# STM32H743V register map
File version: 2.4
CPU: CM7 r0p1, little endian, MPU, FPU, 4 interrupt priority bits
Registers are 32-bit, read-write, reset 0x0 unless marked. A register's access mark holds for its fields unless they carry their own. Offsets are from the block's base; [hi:lo] are bit positions; lines under a group give offsets from that group; {n}, {i} and the like mark numbered series.

## CRC — Cryptographic processor
Base 0x58024C00
0x00 DR reset 0xFFFFFFFF — Data register
  [31:0] DR — Data Register
0x00 DR8 8-bit reset 0xFF (alternate view of DR) — Data register - byte sized
  [7:0] DR8 — Data register bits
0x00 DR16 16-bit reset 0xFFFF (alternate view of DR) — Data register - half-word sized
  [15:0] DR16 — Data register bits
0x04 IDR — Independent Data register
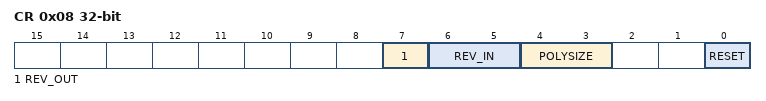
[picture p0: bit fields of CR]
0x08 CR access per field — Control register
  [7] REV_OUT rw — Reverse output data
    0=Normal (Bit order not affected); 1=Reversed (Bit reversed output)
  [6:5] REV_IN rw — Reverse input data
    0=Normal (Bit order not affected); 1=Byte (Bit reversal done by byte); 2=HalfWord (Bit reversal done by half-word); 3=Word (Bit reversal done by word)
  [4:3] POLYSIZE rw — Polynomial size
    0=32-bit polynomial; 1=16-bit polynomial; 2=8-bit polynomial; 3=7-bit polynomial
  [0] RESET wo — RESET bit
    1=Resets the CRC calculation unit and sets the data register to 0xFFFF FFFF
0x10 INIT reset 0xFFFFFFFF — Initial CRC value
  [31:0] INIT — Programmable initial CRC value
0x14 POL reset 0x4C11DB7 — CRC polynomial
  [31:0] POL — Programmable polynomial

## RAMECC1 — ECC controller is associated to each RAM area
Base 0x52009000
Same registers: RAMECC2 0x48023000
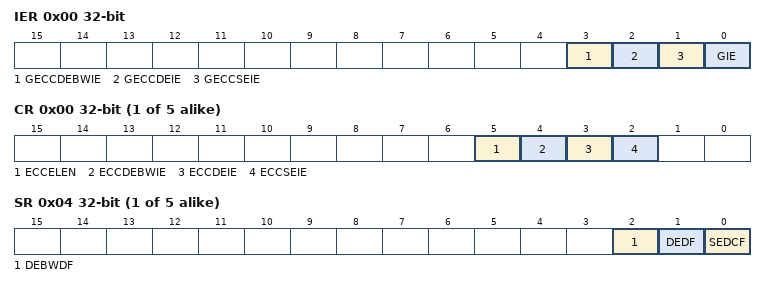
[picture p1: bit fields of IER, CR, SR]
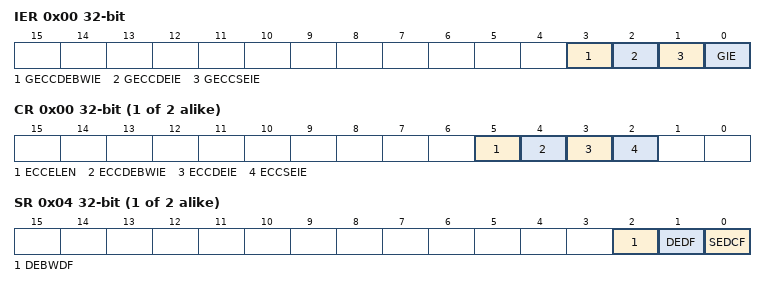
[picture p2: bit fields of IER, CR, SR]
0x00 IER — RAMECC interrupt enable register
  [3] GECCDEBWIE — Global ECC double error on byte write (BW) interrupt enable
  [2] GECCDEIE — Global ECC double error interrupt enable
  [1] GECCSEIE — Global ECC single error interrupt enable
  [0] GIE — Global interrupt enable
{0x0+0x20*i} M{i} (i=1..5) group — Cluster M{i}, containing M?CR, M?SR, M?FAR, M?FDRL, M?FDRH, M?FECR
  0x00 CR — RAMECC monitor x configuration register
    [5] ECCELEN — ECC error latching enable
    [4] ECCDEBWIE — ECC double error on byte write (BW) interrupt enable
    [3] ECCDEIE — ECC double error interrupt enable
    [2] ECCSEIE — ECC single error interrupt enable
  0x04 SR — RAMECC monitor x status register
    [2] DEBWDF — ECC double error on byte write (BW) detected flag
    [1] DEDF — ECC double error detected flag
    [0] SEDCF — ECC single error detected and corrected flag
  0x08 FAR ro — RAMECC monitor x failing address register
    [31:0] FADD — ECC error failing address
  0x0C FDRL ro — RAMECC monitor x failing data low register
    [31:0] FDATAL — Failing data low
  0x10 FDRH ro — RAMECC monitor x failing data high register
    [31:0] FDATAH — Failing data high (64-bit memory)
  0x14 FECR ro — RAMECC monitor x failing ECC error code register
    [31:0] FEC — Failing error code

## RAMECC3 — ECC controller is associated to each RAM area
Base 0x58027000
0x00 IER — RAMECC interrupt enable register
  [3] GECCDEBWIE — Global ECC double error on byte write (BW) interrupt enable
  [2] GECCDEIE — Global ECC double error interrupt enable
  [1] GECCSEIE — Global ECC single error interrupt enable
  [0] GIE — Global interrupt enable
{0x0+0x20*i} M{i} (i=1..2) group — Cluster M{i}, containing M?CR, M?SR, M?FAR, M?FDRL, M?FDRH, M?FECR
  0x00 CR — RAMECC monitor x configuration register
    [5] ECCELEN — ECC error latching enable
    [4] ECCDEBWIE — ECC double error on byte write (BW) interrupt enable
    [3] ECCDEIE — ECC double error interrupt enable
    [2] ECCSEIE — ECC single error interrupt enable
  0x04 SR — RAMECC monitor x status register
    [2] DEBWDF — ECC double error on byte write (BW) detected flag
    [1] DEDF — ECC double error detected flag
    [0] SEDCF — ECC single error detected and corrected flag
  0x08 FAR ro — RAMECC monitor x failing address register
    [31:0] FADD — ECC error failing address
  0x0C FDRL ro — RAMECC monitor x failing data low register
    [31:0] FDATAL — Failing data low
  0x10 FDRH ro — RAMECC monitor x failing data high register
    [31:0] FDATAH — Failing data high (64-bit memory)
  0x14 FECR ro — RAMECC monitor x failing ECC error code register
    [31:0] FEC — Failing error code
